# pse84_a0 register map
Vendor: Infineon Technologies; Series: PSE84_A0; File version: 1.0
CPU: CM33 r0p1, little endian, MPU, FPU, VTOR, 3 interrupt priority bits
Registers are 32-bit, read-write, reset 0x0 unless marked. A register's access mark holds for its fields unless they carry their own. Offsets are from the block's base; [hi:lo] are bit positions; lines under a group give offsets from that group; {n}, {i} and the like mark numbered series; 'fields as' and 'values as' point back to an identical list.

## GFXSS (part 4 of 4)
Base 0x44800000
0x2000 GFXSS_MIPIDSI group — MIPI-DSI Host Controller.
  0x1000 DWCMIPIDSI group — DSI Registers
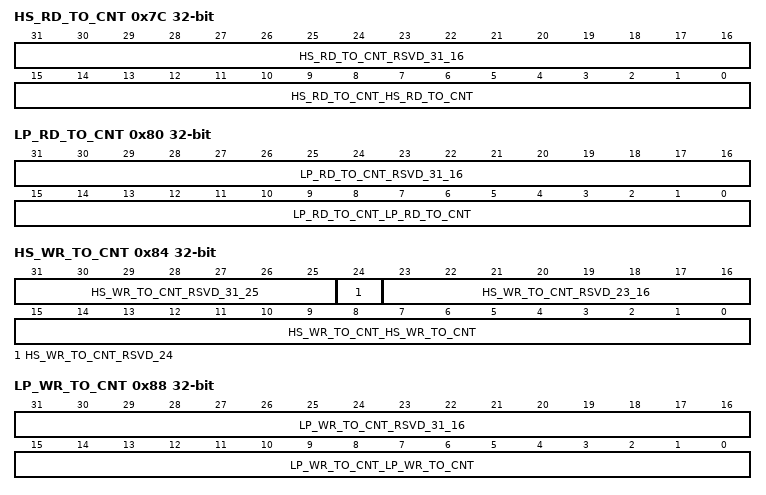
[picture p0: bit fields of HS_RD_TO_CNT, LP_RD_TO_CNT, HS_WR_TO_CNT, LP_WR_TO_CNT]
    0x7C HS_RD_TO_CNT — Configures the Peripheral Response timeout after high-speed Read operations.
      [31:16] HS_RD_TO_CNT_RSVD_31_16 ro
      [15:0] HS_RD_TO_CNT_HS_RD_TO_CNT — This field sets a period for which DWC_mipi_dsi_host keeps the link still, after sending a high-speed Read operation. This period is measured in cycles of lanebyteclk, starts to count when the D-PHY enters stop state and causes no interrupts.
    0x80 LP_RD_TO_CNT — Configures the Peripheral Response timeout after low-power Read operations.
      [31:16] LP_RD_TO_CNT_RSVD_31_16 ro
      [15:0] LP_RD_TO_CNT_LP_RD_TO_CNT — This field sets a period for which DWC_mipi_dsi_host keeps the link still, after sending a low-power Read operation. This period is measured in cycles of lanebyteclk, starts to count when the D-PHY enters stop state and causes no interrupts.
    0x84 HS_WR_TO_CNT — Configures the Peripheral Response timeout after high-speed Write operations.
      [31:25] HS_WR_TO_CNT_RSVD_31_25 ro
      [24] HS_WR_TO_CNT_RSVD_24 ro
      [23:16] HS_WR_TO_CNT_RSVD_23_16 ro
      [15:0] HS_WR_TO_CNT_HS_WR_TO_CNT — This field sets a period for which DWC_mipi_dsi_host keeps the link still, after sending a high-speed Write operation. This period is measured in cycles of lanebyteclk, starts to count when the D-PHY enters stop state and causes no interrupts.
    0x88 LP_WR_TO_CNT — Configures the Peripheral Response timeout after low-power Write operations.
      [31:16] LP_WR_TO_CNT_RSVD_31_16 ro
      [15:0] LP_WR_TO_CNT_LP_WR_TO_CNT — This field sets a period for which DWC_mipi_dsi_host keeps the link still, after sending a low-power Write operation. This period is measured in cycles of lanebyteclk, starts to count when the D-PHY enters stop state and causes no interrupts.
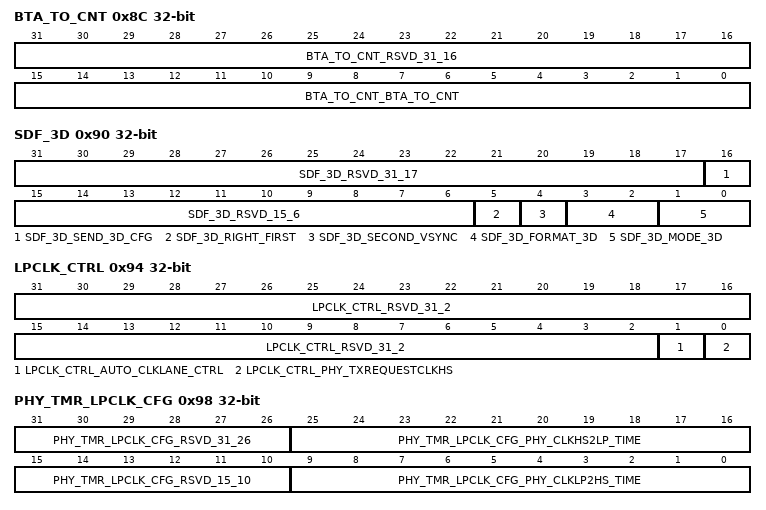
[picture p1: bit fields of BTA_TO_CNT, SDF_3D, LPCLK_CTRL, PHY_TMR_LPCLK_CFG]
    0x8C BTA_TO_CNT — Configures the Peripheral Response timeout after Bus Turnaround completion.
      [31:16] BTA_TO_CNT_RSVD_31_16 ro
      [15:0] BTA_TO_CNT_BTA_TO_CNT — This field sets a period for which DWC_mipi_dsi_host keeps the link still, after completing a Bus Turnaround. This period is measured in cycles of lanebyteclk, starts to count when the D-PHY enters stop state and causes no interrupts.
    0x90 SDF_3D — Stores 3D control information for VSS packets in video mode.
      [31:17] SDF_3D_RSVD_31_17 ro
      [16] SDF_3D_SEND_3D_CFG — When set, causes the next VSS packet to include 3D control payload in every VSS packet.
      [15:6] SDF_3D_RSVD_15_6 ro
      [5] SDF_3D_RIGHT_FIRST — This bit defines the left/right order:
        0=LFIRST ((none)); 1=RFIRST ((none))
      [4] SDF_3D_SECOND_VSYNC — This field defines whether there is a second VSYNC pulse between Left and Right Images, when 3D Image Format is Frame-based:
        0=NOSYNC ((none)); 1=SYNC ((none))
      [3:2] SDF_3D_FORMAT_3D — This field defines 3D Image Format:
        1=FRAME ((none)); 0=LINE ((none)); 2=PIXEL ((none)); 3=RSVD ((none))
      [1:0] SDF_3D_MODE_3D — This field defines 3D Mode On/Off and Display Orientation:
        {v}=MODE{v} ((none)) (v=0..3)
    0x94 LPCLK_CTRL — Configures the possibility for using non continuous clock in the clock lane.
      [31:2] LPCLK_CTRL_RSVD_31_2 ro
      [1] LPCLK_CTRL_AUTO_CLKLANE_CTRL — This bit enables the automatic mechanism to stop providing clock in the clock lane when time allows.
      [0] LPCLK_CTRL_PHY_TXREQUESTCLKHS — This bit controls the D-PHY PPI txrequestclkhs signal.
    0x98 PHY_TMR_LPCLK_CFG — Sets the time that DWC_mipi_dsi_host assumes in calculations for the clock lane to switch between high-speed and low-power.
      [31:26] PHY_TMR_LPCLK_CFG_RSVD_31_26 ro
      [25:16] PHY_TMR_LPCLK_CFG_PHY_CLKHS2LP_TIME — This field configures the maximum time that the D-PHY clock lane takes to go from high-speed to low-power transmission measured in lane byte clock cycles.
      [15:10] PHY_TMR_LPCLK_CFG_RSVD_15_10 ro
      [9:0] PHY_TMR_LPCLK_CFG_PHY_CLKLP2HS_TIME — This field configures the maximum time that the D-PHY clock lane takes to go from low-power to high-speed transmission measured in lane byte clock cycles.
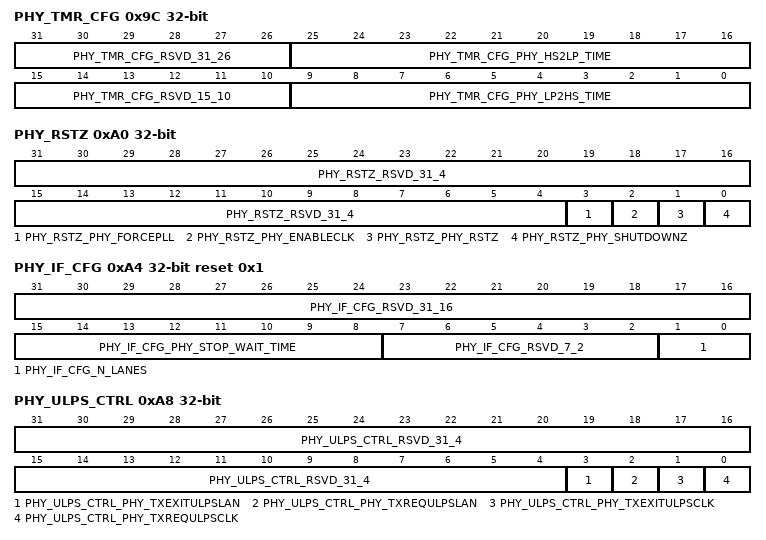
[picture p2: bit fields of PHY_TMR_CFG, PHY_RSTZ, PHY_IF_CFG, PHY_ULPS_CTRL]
    0x9C PHY_TMR_CFG — Sets the time that DWC_mipi_dsi_host assumes in calculations for the data lanes to switch between high-speed and low-power.
      [31:26] PHY_TMR_CFG_RSVD_31_26 ro
      [25:16] PHY_TMR_CFG_PHY_HS2LP_TIME — This field configures the maximum time that the D-PHY data lanes take to go from high-speed to low-power transmission measured in lane byte clock cycles.
      [15:10] PHY_TMR_CFG_RSVD_15_10 ro
      [9:0] PHY_TMR_CFG_PHY_LP2HS_TIME — This field configures the maximum time that the D-PHY data lanes take to go from low-power to high-speed transmission measured in lane byte clock cycles.
    0xA0 PHY_RSTZ — Controls resets and the PLL of the D-PHY.
      [31:4] PHY_RSTZ_RSVD_31_4 ro
      [3] PHY_RSTZ_PHY_FORCEPLL — When the D-PHY is in ULPS, this bit enables the D-PHY PLL.
      [2] PHY_RSTZ_PHY_ENABLECLK — When set to 1, this bit enables the D-PHY Clock Lane Module.
      [1] PHY_RSTZ_PHY_RSTZ — When set to 0, this bit places the digital section of the D-PHY in the reset state.
      [0] PHY_RSTZ_PHY_SHUTDOWNZ — When set to 0, this bit places the complete D-PHY macro in power-down state.
    0xA4 PHY_IF_CFG reset 0x1 — Configures the number of active lanes and the minimum time to remain in stop state.
      [31:16] PHY_IF_CFG_RSVD_31_16 ro
      [15:8] PHY_IF_CFG_PHY_STOP_WAIT_TIME — This field configures the minimum time PHY needs to stay in StopState before requesting an high-speed transmission
      [7:2] PHY_IF_CFG_RSVD_7_2 ro
      [1:0] PHY_IF_CFG_N_LANES — This field configures the number of active data lanes:
        3=FOURLANES ((none)); 0=ONELANES ((none)); 2=THREELANES ((none)); 1=TWOLANES ((none))
    0xA8 PHY_ULPS_CTRL — Configures entering and leaving ULPS in the D-PHY.
      [31:4] PHY_ULPS_CTRL_RSVD_31_4 ro
      [3] PHY_ULPS_CTRL_PHY_TXEXITULPSLAN — ULPS mode Exit on all active data lanes.
      [2] PHY_ULPS_CTRL_PHY_TXREQULPSLAN — ULPS mode Request on all active data lanes.
      [1] PHY_ULPS_CTRL_PHY_TXEXITULPSCLK — ULPS mode Exit on clock lane.
      [0] PHY_ULPS_CTRL_PHY_TXREQULPSCLK — ULPS mode Request on clock lane.
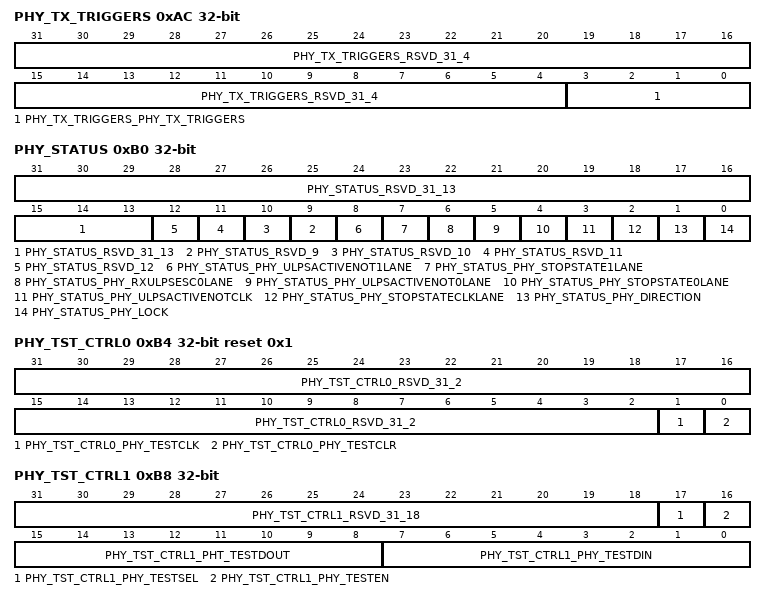
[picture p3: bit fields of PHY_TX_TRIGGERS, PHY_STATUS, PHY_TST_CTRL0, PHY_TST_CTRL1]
    0xAC PHY_TX_TRIGGERS — Configures the pins that activate triggers in the D-PHY.
      [31:4] PHY_TX_TRIGGERS_RSVD_31_4 ro
      [3:0] PHY_TX_TRIGGERS_PHY_TX_TRIGGERS — This field controls the trigger transmissions.
    0xB0 PHY_STATUS ro (reset mask 0xFFFFE000) — Contains information about the status of the D-PHY.
      [31:13] PHY_STATUS_RSVD_31_13
      [n] PHY_STATUS_RSVD_{n} (n=9..12)
      [8] PHY_STATUS_PHY_ULPSACTIVENOT1LANE — This bit indicates the status of ulpsactivenot1lane D-PHY signal.
      [7] PHY_STATUS_PHY_STOPSTATE1LANE — This bit indicates the status of phystopstate1lane D-PHY signal.
      [6] PHY_STATUS_PHY_RXULPSESC0LANE — This bit indicates the status of rxulpsesc0lane D-PHY signal.
      [5] PHY_STATUS_PHY_ULPSACTIVENOT0LANE — This bit indicates the status of ulpsactivenot0lane D-PHY signal.
      [4] PHY_STATUS_PHY_STOPSTATE0LANE — This bit indicates the status of phystopstate0lane D-PHY signal.
      [3] PHY_STATUS_PHY_ULPSACTIVENOTCLK — This bit indicates the status of phyulpsactivenotclk D-PHY signal.
      [2] PHY_STATUS_PHY_STOPSTATECLKLANE — This bit indicates the status of phystopstateclklane D-PHY signal.
      [1] PHY_STATUS_PHY_DIRECTION — This bit indicates the status of phydirection D-PHY signal.
      [0] PHY_STATUS_PHY_LOCK — This bit indicates the status of phylock D-PHY signal.
    0xB4 PHY_TST_CTRL0 reset 0x1 — Controls clock and clear pins of the D-PHY vendor specific interface.
      [31:2] PHY_TST_CTRL0_RSVD_31_2 ro
      [1] PHY_TST_CTRL0_PHY_TESTCLK — This bit is used to clock the TESTDIN bus into the D-PHY.
      [0] PHY_TST_CTRL0_PHY_TESTCLR — PHY test interface clear (active high).
    0xB8 PHY_TST_CTRL1 — Controls data and enable pins of the D-PHY vendor specific interface.
      [31:18] PHY_TST_CTRL1_RSVD_31_18 ro
      [17] PHY_TST_CTRL1_PHY_TESTSEL — PHY BiDIR MUX selector
      [16] PHY_TST_CTRL1_PHY_TESTEN — PHY test interface operation selector:
        1=WRITEADDR ((none)); 0=WRITEDATA ((none))
      [15:8] PHY_TST_CTRL1_PHT_TESTDOUT ro — PHY output 8-bit data bus for read-back and internal probing functionalities.
      [7:0] PHY_TST_CTRL1_PHY_TESTDIN — PHY test interface input 8-bit data bus for internal register programming and test functionalities access.
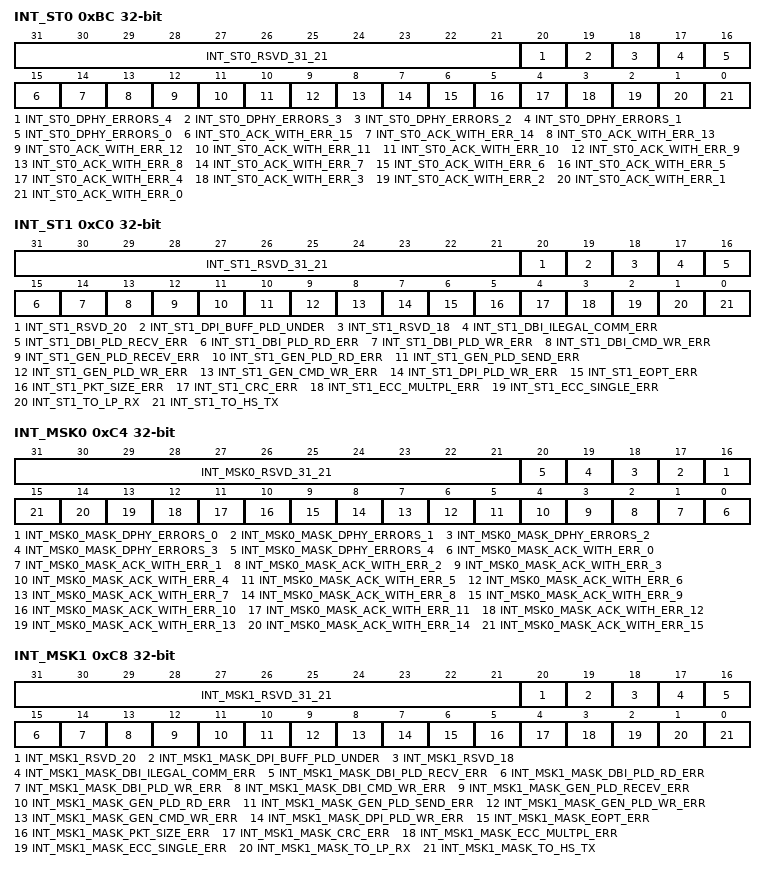
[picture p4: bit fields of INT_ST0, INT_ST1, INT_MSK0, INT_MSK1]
    0xBC INT_ST0 ro — Contains the status of interrupt sources from acknowledge reports and the D-PHY.
      [31:21] INT_ST0_RSVD_31_21
      [20] INT_ST0_DPHY_ERRORS_4 — This bit indicates LP1 contention error ErrContentionLP1 from Lane 0.
      [19] INT_ST0_DPHY_ERRORS_3 — This bit indicates LP0 contention error ErrContentionLP0 from Lane 0.
      [18] INT_ST0_DPHY_ERRORS_2 — This bit indicates control error ErrControl from Lane 0.
      [17] INT_ST0_DPHY_ERRORS_1 — This bit indicates ErrSyncEsc low-power data transmission synchronization error from Lane 0.
      [16] INT_ST0_DPHY_ERRORS_0 — This bit indicates ErrEsc escape entry error from Lane 0.
      [15] INT_ST0_ACK_WITH_ERR_15 — This bit retrieves the DSI protocol violation from the Acknowledge error report.
      [14] INT_ST0_ACK_WITH_ERR_14
      [13] INT_ST0_ACK_WITH_ERR_13 — This bit retrieves the invalid transmission length from the Acknowledge error report.
      [12] INT_ST0_ACK_WITH_ERR_12 — This bit retrieves the DSI VC ID Invalid from the Acknowledge error report.
      [11] INT_ST0_ACK_WITH_ERR_11 — This bit retrieves the not recognized DSI data type from the Acknowledge error report.
      [10] INT_ST0_ACK_WITH_ERR_10 — This bit retrieves the checksum error (long packet only) from the Acknowledge error report.
      [9] INT_ST0_ACK_WITH_ERR_9 — This bit retrieves the ECC error, multi-bit (detected, not corrected) from the Acknowledge error report.
      [8] INT_ST0_ACK_WITH_ERR_8 — This bit retrieves the ECC error, single-bit (detected and corrected) from the Acknowledge error report.
      [7] INT_ST0_ACK_WITH_ERR_7 — This bit retrieves the Contention Detected error from the Acknownledge error report.
      [6] INT_ST0_ACK_WITH_ERR_6 — This bit retrieves the False Control error from the Acknowledge error report.
      [5] INT_ST0_ACK_WITH_ERR_5 — This bit retrieves the Peripheral Timeout error from the Acknowledge error report.
      [4] INT_ST0_ACK_WITH_ERR_4 — This bit retrieves the low-power Transmit Sync error from the Acknowledge error report.
      [3] INT_ST0_ACK_WITH_ERR_3 — This bit retrieves the Escape Mode Entry Command error from the Acknowledge error report.
      [2] INT_ST0_ACK_WITH_ERR_2 — This bit retrieves the EoT Sync error from the Acknowledge error report.
      [1] INT_ST0_ACK_WITH_ERR_1 — This bit retrieves the SoT Sync error from the Acknowledge error report.
      [0] INT_ST0_ACK_WITH_ERR_0 — This bit retrieves the SoT error from the Acknowledge error report.
    0xC0 INT_ST1 ro — Contains the status of interrupt sources related to timeouts, ECC, CRC, packet size, EoTp, Generic and DBI interfaces.
      [31:21] INT_ST1_RSVD_31_21
      [20] INT_ST1_RSVD_20
      [19] INT_ST1_DPI_BUFF_PLD_UNDER — This bit indicates that an underflow has occurred when reading payload to build DSI packet for video mode
      [18] INT_ST1_RSVD_18
      [17] INT_ST1_DBI_ILEGAL_COMM_ERR — This bit indicates that an attempt to write an illegal command on the DBI interface is made and the controller is blocked by transmission.
      [16] INT_ST1_DBI_PLD_RECV_ERR — This bit indicates that during a DBI read back packet, the payload FIFO becomes full and the received data is corrupted.
      [15] INT_ST1_DBI_PLD_RD_ERR — This bit indicates that during a DCS read data, the payload FIFO goes empty and the data sent to the interface is corrupted.
      [14] INT_ST1_DBI_PLD_WR_ERR — This bit indicates that the system tried to write the payload data through the DBI interface and the FIFO is full. Therefore, the command is not written.
      [13] INT_ST1_DBI_CMD_WR_ERR — This bit indicates that the system tried to write a command through the DBI but the command FIFO is full. Therefore, the command is not written.
      [12] INT_ST1_GEN_PLD_RECEV_ERR — This bit indicates that during a generic interface packet read back, the payload FIFO becomes full and the received data is corrupted.
      [11] INT_ST1_GEN_PLD_RD_ERR — This bit indicates that during a DCS read data, the payload FIFO becomes empty and the data sent to the interface is corrupted.
      [10] INT_ST1_GEN_PLD_SEND_ERR — This bit indicates that during a Generic interface packet build, the payload FIFO becomes empty and corrupt data is sent.
      [9] INT_ST1_GEN_PLD_WR_ERR — This bit indicates that the system tried to write a payload data through the Generic interface and the FIFO is full. Therefore, the payload is not written.
      [8] INT_ST1_GEN_CMD_WR_ERR — This bit indicates that the system tried to write a command through the Generic interface and the FIFO is full. Therefore, the command is not written.
      [7] INT_ST1_DPI_PLD_WR_ERR — This bit indicates that during a DPI pixel line storage, the payload FIFO becomes full and the data stored is corrupted.
      [6] INT_ST1_EOPT_ERR — This bit indicates that the EoTp packet has not been received at the end of the incoming peripheral transmission.
      [5] INT_ST1_PKT_SIZE_ERR — This bit indicates that the packet size error has been detected during the packet reception.
      [4] INT_ST1_CRC_ERR — This bit indicates that the CRC error has been detected in the received packet payload.
      [3] INT_ST1_ECC_MULTPL_ERR — This bit indicates that the ECC multiple error has been detected in a received packet.
      [2] INT_ST1_ECC_SINGLE_ERR — This bit indicates that the ECC single error has been detected and corrected in a received packet.
      [1] INT_ST1_TO_LP_RX — This bit indicates that the low-power reception timeout counter reached the end and contention has been detected.
      [0] INT_ST1_TO_HS_TX — This bit indicates that the high-speed transmission timeout counter reached the end and contention has been detected.
    0xC4 INT_MSK0 — Configures masks for the sources of interrupts that affect the INT_ST0 register. Write 1 to un-mask each error report.
      [31:21] INT_MSK0_RSVD_31_21 ro
      [n+16] INT_MSK0_MASK_DPHY_ERRORS_{n} (n=0..4) — Mask for dphy_errors_{n}
      [n] INT_MSK0_MASK_ACK_WITH_ERR_{n} (n=0..15) — Mask for ack_with_err_{n}
    0xC8 INT_MSK1 — Configures masks for the sources of interrupts that affect the INT_ST1 register.
      [31:21] INT_MSK1_RSVD_31_21 ro
      [20] INT_MSK1_RSVD_20 ro
      [19] INT_MSK1_MASK_DPI_BUFF_PLD_UNDER — Mask for dpi_buff_pld_under
      [18] INT_MSK1_RSVD_18 ro
      [17] INT_MSK1_MASK_DBI_ILEGAL_COMM_ERR — Mask for dbi_ilegal_comm_err
      [16] INT_MSK1_MASK_DBI_PLD_RECV_ERR — Mask for dbi_pld_recv_err
      [15] INT_MSK1_MASK_DBI_PLD_RD_ERR — Mask for dbi_pld_rd_err
      [14] INT_MSK1_MASK_DBI_PLD_WR_ERR — Mask for dbi_pld_wr_err
      [13] INT_MSK1_MASK_DBI_CMD_WR_ERR — Mask for dbi_cmd_wr_err
      [12] INT_MSK1_MASK_GEN_PLD_RECEV_ERR — Mask for gen_pld_recev_err
      [11] INT_MSK1_MASK_GEN_PLD_RD_ERR — Mask for gen_pld_rd_err
      [10] INT_MSK1_MASK_GEN_PLD_SEND_ERR — Mask for gen_pld_send_err
      [9] INT_MSK1_MASK_GEN_PLD_WR_ERR — Mask for gen_pld_wr_err
      [8] INT_MSK1_MASK_GEN_CMD_WR_ERR — Mask for gen_cmd_wr_err
      [7] INT_MSK1_MASK_DPI_PLD_WR_ERR — Mask for dpi_pld_wr_err
      [6] INT_MSK1_MASK_EOPT_ERR — Mask for eopt_err
      [5] INT_MSK1_MASK_PKT_SIZE_ERR — Mask for pkt_size_err
      [4] INT_MSK1_MASK_CRC_ERR — Mask for crc_err
      [3] INT_MSK1_MASK_ECC_MULTPL_ERR — Mask for ecc_multpl_err
      [2] INT_MSK1_MASK_ECC_SINGLE_ERR — Mask for ecc_single_err
      [1] INT_MSK1_MASK_TO_LP_RX — Mask for to_lp_rx
      [0] INT_MSK1_MASK_TO_HS_TX — Mask for to_hs_tx
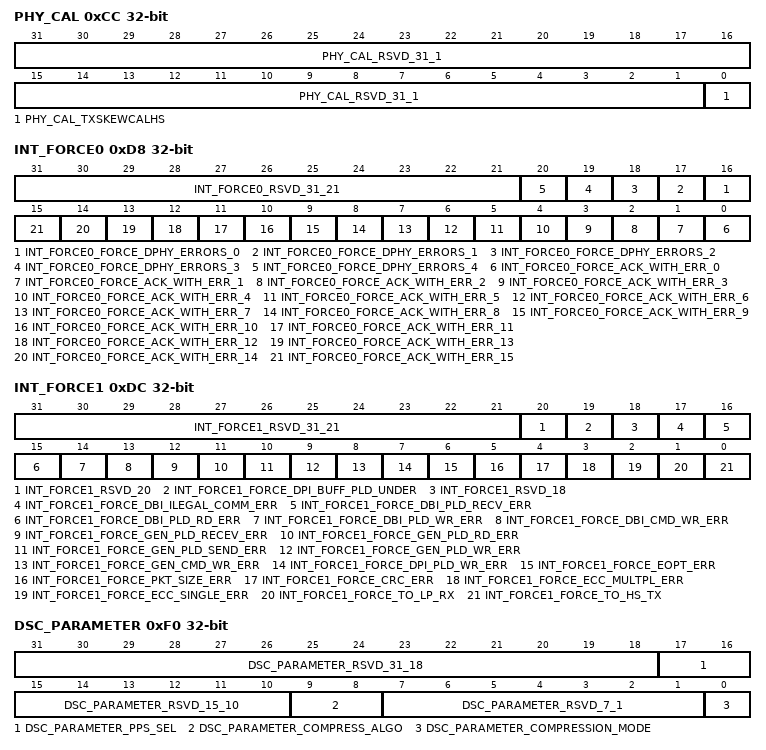
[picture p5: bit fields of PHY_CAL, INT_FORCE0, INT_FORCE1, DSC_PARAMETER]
    0xCC PHY_CAL — Controls the skew calibration of D-PHY.
      [31:1] PHY_CAL_RSVD_31_1 ro
      [0] PHY_CAL_TXSKEWCALHS — High-speed skew calibration is started when txskewcalhs is set high (assuming that PHY is in Stop state).
    0xD8 INT_FORCE0 — Forces interrupt that affect the INT_ST0 register.
      [31:21] INT_FORCE0_RSVD_31_21 ro
      [n+16] INT_FORCE0_FORCE_DPHY_ERRORS_{n} (n=0..4) — Force dphy_errors_{n}
      [n] INT_FORCE0_FORCE_ACK_WITH_ERR_{n} (n=0..15) — Force ack_with_err_{n}
    0xDC INT_FORCE1 — Forces interrupts that affect the INT_ST1 register.
      [31:21] INT_FORCE1_RSVD_31_21 ro
      [20] INT_FORCE1_RSVD_20 ro
      [19] INT_FORCE1_FORCE_DPI_BUFF_PLD_UNDER — Force for dpi_buff_pld_under.
      [18] INT_FORCE1_RSVD_18 ro
      [17] INT_FORCE1_FORCE_DBI_ILEGAL_COMM_ERR — Force dbi_ilegal_comm_err.
      [16] INT_FORCE1_FORCE_DBI_PLD_RECV_ERR — Force dbi_pld_recv_err.
      [15] INT_FORCE1_FORCE_DBI_PLD_RD_ERR — Force dbi_pld_rd_err.
      [14] INT_FORCE1_FORCE_DBI_PLD_WR_ERR — Force dbi_pld_wr_err.
      [13] INT_FORCE1_FORCE_DBI_CMD_WR_ERR — Force dbi_cmd_wr_err.
      [12] INT_FORCE1_FORCE_GEN_PLD_RECEV_ERR — Force gen_pld_recev_err
      [11] INT_FORCE1_FORCE_GEN_PLD_RD_ERR — Force gen_pld_rd_err
      [10] INT_FORCE1_FORCE_GEN_PLD_SEND_ERR — Force gen_pld_send_err
      [9] INT_FORCE1_FORCE_GEN_PLD_WR_ERR — Force gen_pld_wr_err
      [8] INT_FORCE1_FORCE_GEN_CMD_WR_ERR — Force gen_cmd_wr_err
      [7] INT_FORCE1_FORCE_DPI_PLD_WR_ERR — Force dpi_pld_wr_err
      [6] INT_FORCE1_FORCE_EOPT_ERR — Force eopt_err
      [5] INT_FORCE1_FORCE_PKT_SIZE_ERR — Force pkt_size_err
      [4] INT_FORCE1_FORCE_CRC_ERR — Force crc_err
      [3] INT_FORCE1_FORCE_ECC_MULTPL_ERR — Force ecc_multpl_err
      [2] INT_FORCE1_FORCE_ECC_SINGLE_ERR — Force ecc_single_err
      [1] INT_FORCE1_FORCE_TO_LP_RX — Force to_lp_rx
      [0] INT_FORCE1_FORCE_TO_HS_TX — Force to_hs_tx
    0xF0 DSC_PARAMETER — Configures Display Stream Compression.
      [31:18] DSC_PARAMETER_RSVD_31_18 ro
      [17:16] DSC_PARAMETER_PPS_SEL — This field indicates the PPS selector:
        {v}=PPSSEL{v} ((none)) (v=0..3)
      [15:10] DSC_PARAMETER_RSVD_15_10 ro
      [9:8] DSC_PARAMETER_COMPRESS_ALGO — This field indicates the algorithm identifier:
        {v}=ALGO{v} ((none)) (v=0..3)
      [7:1] DSC_PARAMETER_RSVD_7_1 ro
      [0] DSC_PARAMETER_COMPRESSION_MODE — When set to 1, this bit enables the compression mode.
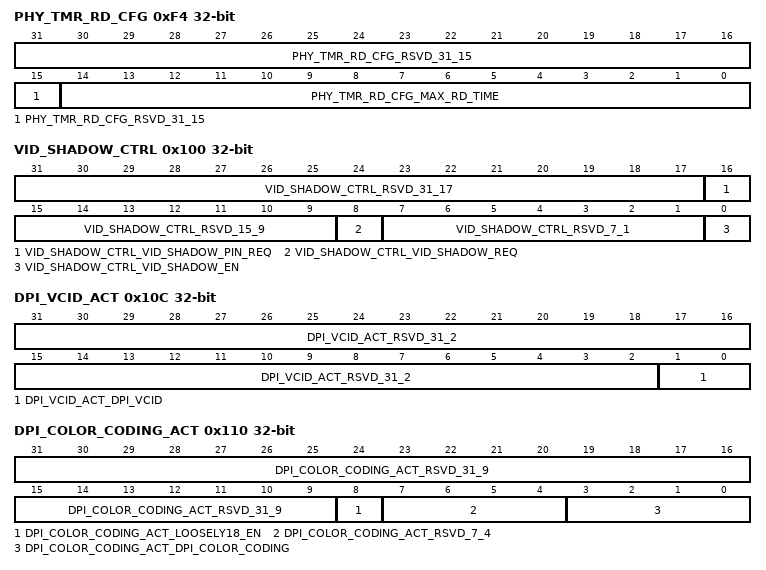
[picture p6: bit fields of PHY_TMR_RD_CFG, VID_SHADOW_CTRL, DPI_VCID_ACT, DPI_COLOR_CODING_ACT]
    0xF4 PHY_TMR_RD_CFG — Configures times related to PHY to perform some operations in lane byte clock cycles.
      [31:15] PHY_TMR_RD_CFG_RSVD_31_15 ro
      [14:0] PHY_TMR_RD_CFG_MAX_RD_TIME — This field configures the maximum time required to perform a read command in lane byte clock cycles. This register can only be modified when no read command is in progress.
    0x100 VID_SHADOW_CTRL — Controls dpi shadow feature
      [31:17] VID_SHADOW_CTRL_RSVD_31_17 ro
      [16] VID_SHADOW_CTRL_VID_SHADOW_PIN_REQ — When set to 1, the video request is done by external pin. In this mode vid_shadow_req is ignored.
      [15:9] VID_SHADOW_CTRL_RSVD_15_9 ro
      [8] VID_SHADOW_CTRL_VID_SHADOW_REQ — When set to 1, this bit request that the dpi registers from regbank are copied to the auxiliary registers. When the request is completed this bit is auto clear.
      [7:1] VID_SHADOW_CTRL_RSVD_7_1 ro
      [0] VID_SHADOW_CTRL_VID_SHADOW_EN — When set to 1, DPI receives the active configuration from the auxiliary registers. When the feature is set at the same time than vid_shadow_req the auxiliary registers are automatically updated.
    0x10C DPI_VCID_ACT ro — Holds the value that controller is using for DPI_VCID.
      [31:2] DPI_VCID_ACT_RSVD_31_2
      [1:0] DPI_VCID_ACT_DPI_VCID — This field specifies the DPI virtual channel id that is indexed to the Video mode packets.
    0x110 DPI_COLOR_CODING_ACT ro — Holds the value that controller is using for DPI_COLOR_CODING.
      [31:9] DPI_COLOR_CODING_ACT_RSVD_31_9
      [8] DPI_COLOR_CODING_ACT_LOOSELY18_EN — When 1, this bit activates loosely packed variant to 18-bit configurations.
      [7:4] DPI_COLOR_CODING_ACT_RSVD_7_4
      [3:0] DPI_COLOR_CODING_ACT_DPI_COLOR_CODING — This field configures the DPI color for Video Mode/eDPI Command Mode coding as follows:
        {v}=CC{v:02} ((none)) (v=0..15)
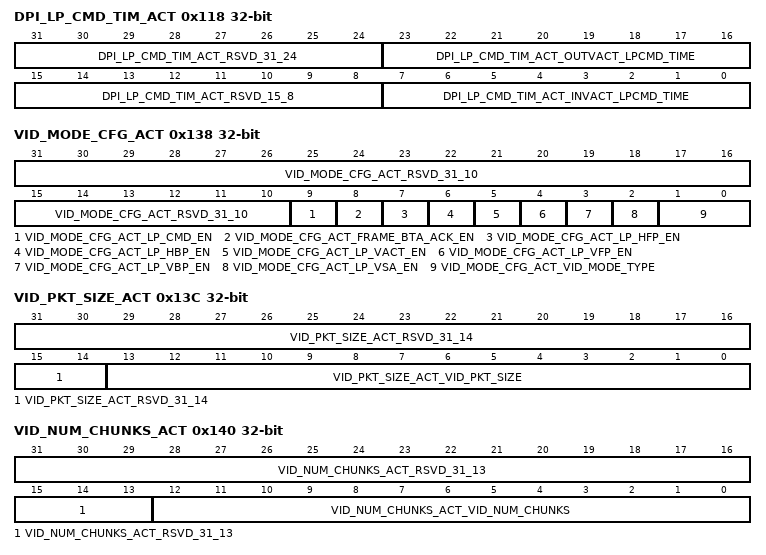
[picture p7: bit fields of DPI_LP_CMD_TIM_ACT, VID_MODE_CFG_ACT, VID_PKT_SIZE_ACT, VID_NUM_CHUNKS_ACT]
    0x118 DPI_LP_CMD_TIM_ACT ro — Holds the value that controller is using for DPI_LP_CMD_TIM.
      [31:24] DPI_LP_CMD_TIM_ACT_RSVD_31_24
      [23:16] DPI_LP_CMD_TIM_ACT_OUTVACT_LPCMD_TIME — This field is used for the transmission of commands in low-power mode. It specifies the size, in bytes, of the largest packet that can fit in a line during the VSA, VBP, and VFP regions.
      [15:8] DPI_LP_CMD_TIM_ACT_RSVD_15_8
      [7:0] DPI_LP_CMD_TIM_ACT_INVACT_LPCMD_TIME — This field is used for the transmission of commands in low-power mode. It specifies the size, in bytes, of the largest packet that can fit in a line during the VACT region.
    0x138 VID_MODE_CFG_ACT ro — Holds the value that controller is using for VID_MODE_CFG.
      [31:10] VID_MODE_CFG_ACT_RSVD_31_10
      [9] VID_MODE_CFG_ACT_LP_CMD_EN — When 1, this bit enables the command transmission only in low-power mode.
      [8] VID_MODE_CFG_ACT_FRAME_BTA_ACK_EN — When 1, this bit enables the request for an acknowledge response at the end of a frame.
      [7] VID_MODE_CFG_ACT_LP_HFP_EN — When 1, this bit enables the return to low-power inside the HFP period when timing allows.
      [6] VID_MODE_CFG_ACT_LP_HBP_EN — When 1, this bit enables the return to low-power inside the HBP period when timing allows.
      [5] VID_MODE_CFG_ACT_LP_VACT_EN — When 1, this bit enables the return to low-power inside the VACT period when timing allows.
      [4] VID_MODE_CFG_ACT_LP_VFP_EN — When 1, this bit enables the return to low-power inside the VFP period when timing allows.
      [3] VID_MODE_CFG_ACT_LP_VBP_EN — When 1, this bit enables the return to low-power inside the VBP period when timing allows.
      [2] VID_MODE_CFG_ACT_LP_VSA_EN — When 1, this bit enables the return to low-power inside the VSA period when timing allows.
      [1:0] VID_MODE_CFG_ACT_VID_MODE_TYPE — This field specifies the video mode transmission type as follows:
        {v}=VIDMODE{v} ((none)) (v=0..3)
    0x13C VID_PKT_SIZE_ACT ro — Holds the value that controller is using for VID_PKT_SIZE.
      [31:14] VID_PKT_SIZE_ACT_RSVD_31_14
      [13:0] VID_PKT_SIZE_ACT_VID_PKT_SIZE — This field specifies the number of pixels in a single video packet. For 18-bit not loosely packed this number must be a multiple of 4 and YCbCr Data Types, it must be a multiple of 2, as described in DSI specification.
    0x140 VID_NUM_CHUNKS_ACT ro — This register holds the value that controller is using for VID_NUM_CHUNKS.
      [31:13] VID_NUM_CHUNKS_ACT_RSVD_31_13
      [12:0] VID_NUM_CHUNKS_ACT_VID_NUM_CHUNKS — This register specifies the number of chunks to be transmitted during a Line period (a chunk is pair made of a video packet and a null packet). If set to 0 or 1, video line is still transmitted in a single packet. If set to 1 that packet is part of a chunk, meaning that a null packet follows it (if vid_null_size>0). Otherwise, multiple chunks are used to transmit each video line.
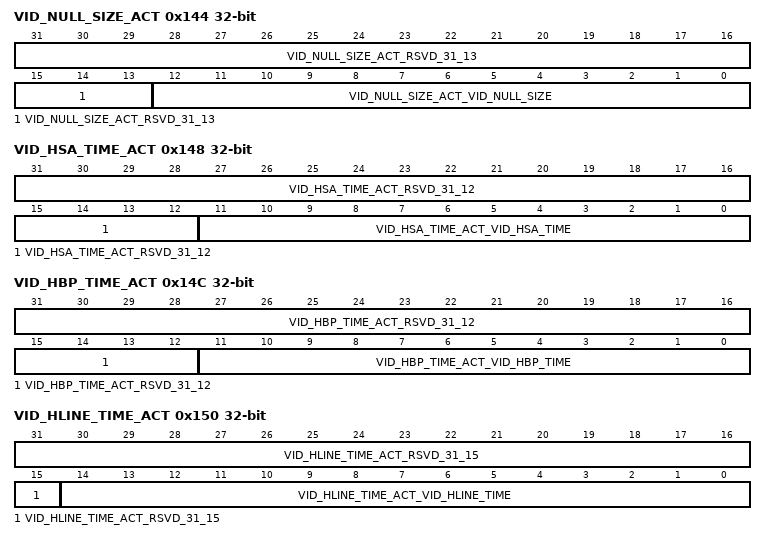
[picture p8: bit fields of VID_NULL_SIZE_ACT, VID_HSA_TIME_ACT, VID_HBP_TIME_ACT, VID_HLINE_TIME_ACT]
    0x144 VID_NULL_SIZE_ACT ro — Holds the value that controller is using for VID_NULL_SIZE.
      [31:13] VID_NULL_SIZE_ACT_RSVD_31_13
      [12:0] VID_NULL_SIZE_ACT_VID_NULL_SIZE — This register specifies the number of bytes inside a null packet. Setting to 0 disables null packets.
    0x148 VID_HSA_TIME_ACT ro — Holds the value that controller is using for VID_HSA_TIME.
      [31:12] VID_HSA_TIME_ACT_RSVD_31_12
      [11:0] VID_HSA_TIME_ACT_VID_HSA_TIME — This field specifies the Horizontal Synchronism Active period in lane byte clock cycles.
    0x14C VID_HBP_TIME_ACT ro — Holds the value that controller is using for VID_HBP_TIME.
      [31:12] VID_HBP_TIME_ACT_RSVD_31_12
      [11:0] VID_HBP_TIME_ACT_VID_HBP_TIME — This field specifies the Horizontal Back Porch period in lane byte clock cycles.
    0x150 VID_HLINE_TIME_ACT ro — Holds the value that controller is using for VID_HLINE_TIME.
      [31:15] VID_HLINE_TIME_ACT_RSVD_31_15
      [14:0] VID_HLINE_TIME_ACT_VID_HLINE_TIME — This field specifies the size of the total line time (HSA+HBP+HACT+HFP) counted in lane byte clock cycles.
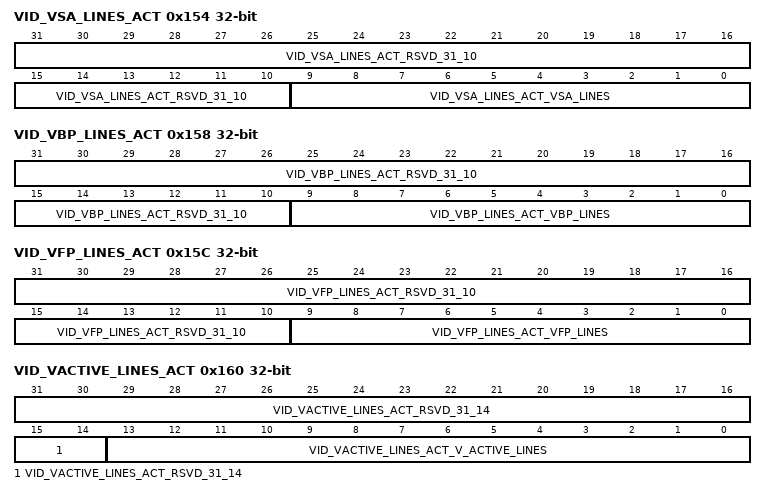
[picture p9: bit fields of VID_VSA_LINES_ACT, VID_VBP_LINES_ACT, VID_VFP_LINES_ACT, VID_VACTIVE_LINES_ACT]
    0x154 VID_VSA_LINES_ACT ro — Holds the value that controller is using for VID_VSA_LINES.
      [31:10] VID_VSA_LINES_ACT_RSVD_31_10
      [9:0] VID_VSA_LINES_ACT_VSA_LINES — This field specifies the Vertical Synchronism Active period measured in number of horizontal lines.
    0x158 VID_VBP_LINES_ACT ro — Holds the value that controller is using for VID_VBP_LINES.
      [31:10] VID_VBP_LINES_ACT_RSVD_31_10
      [9:0] VID_VBP_LINES_ACT_VBP_LINES — This field specifies the Vertical Back Porch period measured in number of horizontal lines.
    0x15C VID_VFP_LINES_ACT ro — Holds the value that controller is using for VID_VFP_LINES.
      [31:10] VID_VFP_LINES_ACT_RSVD_31_10
      [9:0] VID_VFP_LINES_ACT_VFP_LINES — This field specifies the Vertical Front Porch period measured in number of horizontal lines.
    0x160 VID_VACTIVE_LINES_ACT ro — Holds the value that controller is using for VID_VACTIVE_LINES.
      [31:14] VID_VACTIVE_LINES_ACT_RSVD_31_14
      [13:0] VID_VACTIVE_LINES_ACT_V_ACTIVE_LINES — This field specifies the Vertical Active period measured in number of horizontal lines.
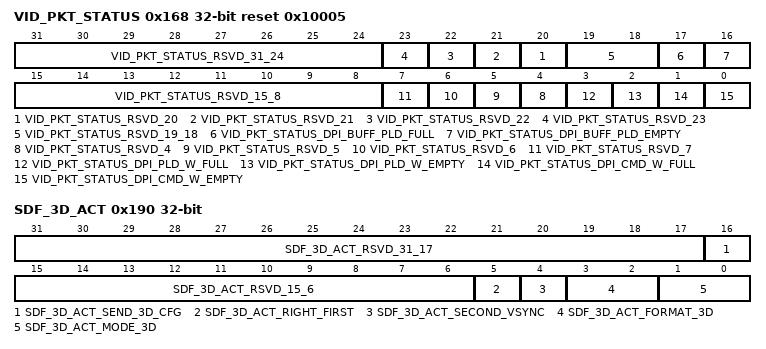
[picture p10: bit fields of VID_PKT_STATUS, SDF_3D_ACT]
    0x168 VID_PKT_STATUS ro reset 0x10005 — Contains information about the status of FIFOs related to DPI and eDPI interfaces.
      [31:24] VID_PKT_STATUS_RSVD_31_24
      [n] VID_PKT_STATUS_RSVD_{n} (n=20..23)
      [19:18] VID_PKT_STATUS_RSVD_19_18
      [17] VID_PKT_STATUS_DPI_BUFF_PLD_FULL — This bit indicates the full status of the payload internal buffer for video Mode. This bit is set to 0 for command Mode.
      [16] VID_PKT_STATUS_DPI_BUFF_PLD_EMPTY — This bit indicates the empty status of the payload internal buffer for video Mode. This bit is set to 0 for command Mode.
      [15:8] VID_PKT_STATUS_RSVD_15_8
      [n] VID_PKT_STATUS_RSVD_{n} (n=4..7)
      [3] VID_PKT_STATUS_DPI_PLD_W_FULL — This bit indicates the full status of write payload FIFO for video Mode. This bit is set to 0 for command Mode.
      [2] VID_PKT_STATUS_DPI_PLD_W_EMPTY — This bit indicates the empty status of write payload FIFO for video Mode. This bit is set to 0 for command Mode.
      [1] VID_PKT_STATUS_DPI_CMD_W_FULL — This bit indicates the full status of write command FIFO for video Mode. This bit is set to 0 for command Mode.
      [0] VID_PKT_STATUS_DPI_CMD_W_EMPTY — This bit indicates the empty status of write command FIFO for video Mode. This bit is set to 0 for command Mode.
    0x190 SDF_3D_ACT ro — Holds the value that controller is using for SDF_3D.
      [31:17] SDF_3D_ACT_RSVD_31_17
      [16] SDF_3D_ACT_SEND_3D_CFG — When set, causes the next VSS packet to include 3D control payload in every VSS packet.
      [15:6] SDF_3D_ACT_RSVD_15_6
      [5] SDF_3D_ACT_RIGHT_FIRST — This bit specifies the left/right order:
        0=LEFTFIRST ((none)); 1=RIGHTFIRST ((none))
      [4] SDF_3D_ACT_SECOND_VSYNC — This field specifies whether there is a second VSYNC pulse between Left and Right Images, when 3D Image Format is Frame-based:
        0=NOSYNCPULSE ((none)); 1=SYNCPULSE ((none))
      [3:2] SDF_3D_ACT_FORMAT_3D — This field specifies 3D Image Format:
        values as GFXSS_MIPIDSI.DWCMIPIDSI.SDF_3D.SDF_3D_FORMAT_3D
      [1:0] SDF_3D_ACT_MODE_3D — This field specifies 3D Mode On/Off and Display Orientation:
        {v}=MODE{v} ((none)) (v=0..3)
